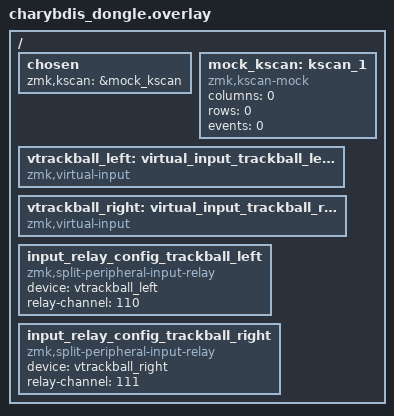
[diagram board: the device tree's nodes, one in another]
#include "charybdis.dtsi"

/ {
    chosen {
        zmk,kscan = &mock_kscan;
    };

    mock_kscan: kscan_1 {
        compatible = "zmk,kscan-mock";
        columns = <0>;
        rows = <0>;
        events = <0>;
    };
};

/ {
	vtrackball_left: virtual_input_trackball_left {
		compatible = "zmk,virtual-input";
	};

	vtrackball_right: virtual_input_trackball_right {
		compatible = "zmk,virtual-input";
	};

	input_relay_config_trackball_left {
		compatible = "zmk,split-peripheral-input-relay";
		device = <&vtrackball_left>;
		relay-channel = <110>;
	};

	input_relay_config_trackball_right {
		compatible = "zmk,split-peripheral-input-relay";
		device = <&vtrackball_right>;
		relay-channel = <111>;
	};
};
